# PIC32MX254F128B device description
Architecture: MIPS; Family: PIC32MX; Series: PIC32MX
Registers are 32-bit, read-write, no defined reset value unless marked. A register's access mark holds for its fields unless they carry their own. Offsets are from the block's base; [hi:lo] are bit positions; {n}, {i} and the like mark numbered series.

## CVR
Instances: CVR 0x1f809800 in periph0
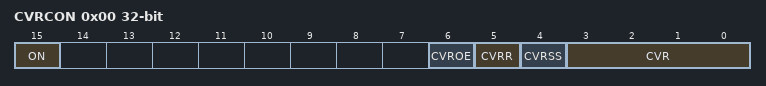
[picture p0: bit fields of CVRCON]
0x00 CVRCON — Comparator Voltage Reference Control Register
  [15] ON — Comparator Voltage Reference On bit
    1=Module is enabled. Setting this bit does not affect other bits in the register.; 0=Module is disabled and does not consume current. Clearing this bit does not affect the other bits in the register.
  [6] CVROE — CVrefout Enable bit
    1=Voltage level is output on CVrefout pin; 0=Voltage level is disconnected from CVrefout pin
  [5] CVRR — CVref Range Selection bit
    1=0 to 0.67 CVrsrc with CVrsrc/24 step size; 0=0.25 CVrsrc to 0.75 CVrsrc with CVrsrc/32 step size
  [4] CVRSS — CVref Source Selection bit
    1=Comparator voltage reference source CVrsrc = (Vref+) - (Vref-); 0=Comparator voltage reference source CVrsrc = AVdd - AVss
  [3:0] CVR — CVref Value Selection
    {v}=(When CVRR is 1) CVREF is ({v}/24) * CVRSRC / (When CVRR is 0) CVREF is CVRSRC/4 + ({v}/32)*CVRSRC (v=0..15)

## DSCTRL
Instances: DSCTRL 0x1f800000 in periph0
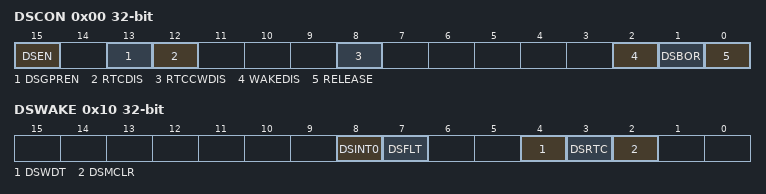
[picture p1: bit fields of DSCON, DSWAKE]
0x00 DSCON — Deep Sleep Control Register
  [15] DSEN — Deep Sleep Enable bit
    1=Deep Sleep mode is entered on a WAIT command; 0=Sleep mode is entered on a WAIT command
  [13] DSGPREN — General Purpose Registers Enable bit
    1=General purpose register retention is enabled in Deep Sleep mode; 0=No general purpose register retention in Deep Sleep mode
  [12] RTCDIS — RTCC Module Disable bit
    1=RTCC module is not enabled; 0=RTCC module is enabled
  [8] RTCCWDIS — RTCC Wake-up Disable bit
    1=Wake-up from RTCC is disabled; 0=Wake-up from RTCC is enabled
  [2] WAKEDIS — Wake-up Source Disable bit
    1=External wake-up source is disabled; 0=External wake-up source is enabled
  [1] DSBOR — Deep Sleep BOR Event Status bit
    1=DSBOREN was enabled and VDD dropped below the DSBOR threshold during Deep Sleep; 0=DSBOREN was disabled, or VDD did not drop below the DSBOR threshold during Deep Sleep
  [0] RELEASE — IO Pin State Release bit
    1=Upon waking from Deep Sleep, the IO pins maintain their previous states; 0=Release IO pins and allow their respective TRIS and LAT bits to control their states
0x10 DSWAKE — Deep Sleep Wake-up Source Register
  [8] DSINT0 — Interrupt-on-Change bit
    1=Interrupt-on-change was asserted during Deep Sleep; 0=Interrupt-on-change was not asserted during Deep Sleep
  [7] DSFLT — Deep Sleep Fault Detected bit
    1=A Fault occurred during Deep Sleep and some Deep Sleep configuration settings may have been corrupted; 0=No Fault was detected during Deep Sleep
  [4] DSWDT — Deep Sleep Watchdog Timer Time-out bit
    1=The Deep Sleep Watchdog Timer timed out during Deep Sleep; 0=The Deep Sleep Watchdog Timer did not time-out during Deep Sleep
  [3] DSRTC — Real-Time Clock and Calendar Alarm bit
    1=The Real-Time Clock and Calendar triggered an alarm during Deep Sleep; 0=The Real-Time Clock and Calendar did not trigger an alarm during Deep Sleep
  [2] DSMCLR — MCLR Event bit
    1=The MCLR pin was active and was asserted during Deep Sleep; 0=The MCLR pin was not active, or was active, but not asserted during Deep Sleep
0x20 DSGPR0
  [31:0] DSGPR
{0x3C+4i} DSGPR{i} (i=1..32)
  [31:0] DSGPR

## HLVD
Instances: HLVD 0x1f801800 in periph1
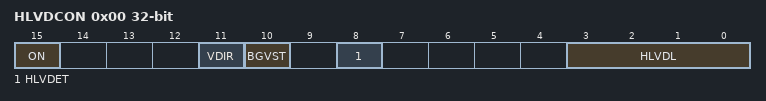
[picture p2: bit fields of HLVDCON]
0x00 HLVDCON — High/Low-Voltage Detect Control Register
  [15] ON — HLVD Module Enable bit
    0=HLVD module is enabled; 0=HLVD module is disabled
  [11] VDIR — Voltage Change Direction Select bit
    1=Event occurs when voltage equals or exceeds the trip point (HLVDL); 0=Event occurs when voltage equals or falls below the trip point (HLVDL)
  [10] BGVST — Band Gap Reference Voltages Stable Status bit
    1=Indicates internal band gap voltage references is stable; 0=Indicates internal band gap voltage reference is not stable
  [8] HLVDET — High/Low-Voltage Detection Event Status bit
    1=Indicates HLVD Event interrupt is active; 0=Indicates HLVD Event interrupt is not active
  [3:0] HLVDL — High/Low-Voltage Detection Limit Select bits
    15=External LVDIN pin; {v}=Reserved; do not use (v=11..14); 10=Selects Trip Point 2.50V (Typ.); 9=Selects Trip Point 2.60V (Typ.); 8=Selects Trip Point 2.81V (Typ.); 7=Selects Trip Point 2.92V (Typ.); 6=Selects Trip Point 3.13V (Typ.); 5=Selects Trip Point 3.44V (Typ.); 4=Selects Trip Point 3.59V (Typ.); {v}=Reserved; do not use (v=0..3)

## Notices in the file
Copyright (c) 2019 Microchip Technology Inc.
SPDX-License-Identifier: Apache-2.0
Licensed under the Apache License, Version 2.0 (the "License");
you may not use this file except in compliance with the License.
You may obtain a copy of the License at
http://www.apache.org/licenses/LICENSE-2.0
Unless required by applicable law or agreed to in writing, software
distributed under the License is distributed on an "AS IS" BASIS,
WITHOUT WARRANTIES OR CONDITIONS OF ANY KIND, either express or implied.
See the License for the specific language governing permissions and
limitations under the License.
